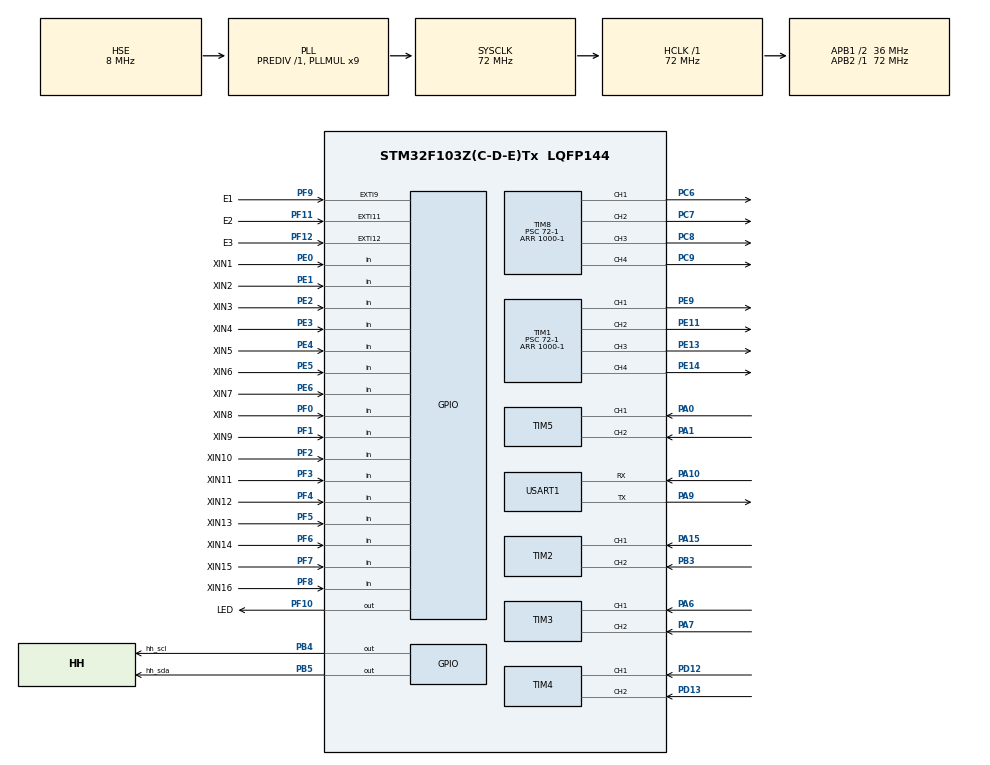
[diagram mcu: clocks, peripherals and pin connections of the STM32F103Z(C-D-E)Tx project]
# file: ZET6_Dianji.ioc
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Mcu.Family=STM32F1
Mcu.Name=STM32F103Z(C-D-E)Tx
Mcu.Package=LQFP144
NVIC.EXTI15_10_IRQn=true\:0\:0\:false\:false\:true\:true\:true\:true
NVIC.EXTI9_5_IRQn=true\:0\:0\:false\:false\:true\:true\:true\:true
NVIC.PriorityGroup=NVIC_PRIORITYGROUP_4
NVIC.TIM8_BRK_IRQn=true\:0\:0\:false\:false\:true\:true\:true\:true
NVIC.TIM8_CC_IRQn=true\:0\:0\:false\:false\:true\:true\:true\:true
NVIC.TIM8_TRG_COM_IRQn=true\:0\:0\:false\:false\:true\:true\:true\:true
NVIC.TIM8_UP_IRQn=true\:0\:0\:false\:false\:true\:true\:true\:true
OSC_IN.Mode=HSE-External-Oscillator
OSC_IN.Signal=RCC_OSC_IN
OSC_OUT.Mode=HSE-External-Oscillator
OSC_OUT.Signal=RCC_OSC_OUT
PA0-WKUP.Signal=S_TIM5_CH1
PA1.Signal=S_TIM5_CH2
PA10.Mode=Asynchronous
PA10.Signal=USART1_RX
PA13.Mode=Serial_Wire
PA13.Signal=SYS_JTMS-SWDIO
PA14.Mode=Serial_Wire
PA14.Signal=SYS_JTCK-SWCLK
PA15.Signal=S_TIM2_CH1_ETR
PA6.Signal=S_TIM3_CH1
PA7.Signal=S_TIM3_CH2
PA9.Mode=Asynchronous
PA9.Signal=USART1_TX
PB3.Signal=S_TIM2_CH2
PB4.GPIO_Label=hh_scl
PB4.GPIO_ModeDefaultOutputPP=GPIO_MODE_OUTPUT_OD
PB4.GPIO_PuPd=GPIO_PULLUP
PB4.GPIO_Speed=GPIO_SPEED_FREQ_HIGH
PB4.PinState=GPIO_PIN_SET
PB4.Signal=GPIO_Output
PB5.GPIO_Label=hh_sda
PB5.GPIO_ModeDefaultOutputPP=GPIO_MODE_OUTPUT_OD
PB5.GPIO_PuPd=GPIO_PULLUP
PB5.GPIO_Speed=GPIO_SPEED_FREQ_HIGH
PB5.PinState=GPIO_PIN_SET
PB5.Signal=GPIO_Output
PC6.Signal=S_TIM8_CH1
PC7.Signal=S_TIM8_CH2
PC8.Signal=S_TIM8_CH3
PC9.Signal=S_TIM8_CH4
PD12.Signal=S_TIM4_CH1
PD13.Signal=S_TIM4_CH2
PE0.GPIO_Label=XIN1
PE0.GPIO_PuPd=GPIO_PULLUP
PE0.Signal=GPIO_Input
PE1.GPIO_Label=XIN2
PE1.GPIO_PuPd=GPIO_PULLUP
PE1.Signal=GPIO_Input
PE11.Signal=S_TIM1_CH2
PE13.Signal=S_TIM1_CH3
PE14.Signal=S_TIM1_CH4
PE2.GPIO_Label=XIN3
PE2.GPIO_PuPd=GPIO_PULLUP
PE2.Signal=GPIO_Input
PE3.GPIO_Label=XIN4
PE3.GPIO_PuPd=GPIO_PULLUP
PE3.Signal=GPIO_Input
PE4.GPIO_Label=XIN5
PE4.GPIO_PuPd=GPIO_PULLUP
PE4.Signal=GPIO_Input
PE5.GPIO_Label=XIN6
PE5.GPIO_PuPd=GPIO_PULLUP
PE5.Signal=GPIO_Input
PE6.GPIO_Label=XIN7
PE6.GPIO_PuPd=GPIO_PULLUP
PE6.Signal=GPIO_Input
PE9.Signal=S_TIM1_CH1
PF0.GPIO_Label=XIN8
PF0.GPIO_PuPd=GPIO_PULLUP
PF0.Signal=GPIO_Input
PF1.GPIO_Label=XIN9
PF1.GPIO_PuPd=GPIO_PULLUP
PF1.Signal=GPIO_Input
PF10.GPIO_Label=LED
PF10.Signal=GPIO_Output
PF11.GPIO_Label=E2
PF11.GPIO_ModeDefaultEXTI=GPIO_MODE_IT_FALLING
PF11.GPIO_PuPd=GPIO_PULLUP
PF11.Signal=GPXTI11
PF12.GPIO_Label=E3
PF12.GPIO_ModeDefaultEXTI=GPIO_MODE_IT_FALLING
PF12.GPIO_PuPd=GPIO_PULLUP
PF12.Signal=GPXTI12
PF2.GPIO_Label=XIN10
PF2.GPIO_PuPd=GPIO_PULLUP
PF2.Signal=GPIO_Input
PF3.GPIO_Label=XIN11
PF3.GPIO_PuPd=GPIO_PULLUP
PF3.Signal=GPIO_Input
PF4.GPIO_Label=XIN12
PF4.GPIO_PuPd=GPIO_PULLUP
PF4.Signal=GPIO_Input
PF5.GPIO_Label=XIN13
PF5.GPIO_PuPd=GPIO_PULLUP
PF5.Signal=GPIO_Input
PF6.GPIO_Label=XIN14
PF6.GPIO_PuPd=GPIO_PULLUP
PF6.Signal=GPIO_Input
PF7.GPIO_Label=XIN15
PF7.GPIO_PuPd=GPIO_PULLUP
PF7.Signal=GPIO_Input
PF8.GPIO_Label=XIN16
PF8.GPIO_PuPd=GPIO_PULLUP
PF8.Signal=GPIO_Input
PF9.GPIO_Label=E1
PF9.GPIO_ModeDefaultEXTI=GPIO_MODE_IT_FALLING
PF9.GPIO_PuPd=GPIO_PULLUP
PF9.Signal=GPXTI9
ProjectManager.HeapSize=0x200
ProjectManager.StackSize=0x400
ProjectManager.TargetToolchain=MDK-ARM V5.32
RCC.AHBFreq_Value=72000000
RCC.APB1CLKDivider=RCC_HCLK_DIV2
RCC.APB1Freq_Value=36000000
RCC.APB1TimFreq_Value=72000000
RCC.APB2Freq_Value=72000000
RCC.APB2TimFreq_Value=72000000
RCC.HCLKFreq_Value=72000000
RCC.PLLMUL=RCC_PLL_MUL9
RCC.PLLSourceVirtual=RCC_PLLSOURCE_HSE
RCC.SYSCLKFreq_VALUE=72000000
RCC.SYSCLKSource=RCC_SYSCLKSOURCE_PLLCLK
RCC.USBFreq_Value=72000000
SH.S_TIM1_CH1.0=TIM1_CH1,PWM Generation1 CH1
SH.S_TIM1_CH2.0=TIM1_CH2,PWM Generation2 CH2
SH.S_TIM1_CH3.0=TIM1_CH3,PWM Generation3 CH3
SH.S_TIM1_CH4.0=TIM1_CH4,PWM Generation4 CH4
SH.S_TIM2_CH1_ETR.0=TIM2_CH1,Encoder_Interface
SH.S_TIM2_CH2.0=TIM2_CH2,Encoder_Interface
SH.S_TIM3_CH1.0=TIM3_CH1,Encoder_Interface
SH.S_TIM3_CH2.0=TIM3_CH2,Encoder_Interface
SH.S_TIM4_CH1.0=TIM4_CH1,Encoder_Interface
SH.S_TIM4_CH2.0=TIM4_CH2,Encoder_Interface
SH.S_TIM5_CH1.0=TIM5_CH1,Encoder_Interface
SH.S_TIM5_CH2.0=TIM5_CH2,Encoder_Interface
SH.S_TIM8_CH1.0=TIM8_CH1,PWM Generation1 CH1
SH.S_TIM8_CH2.0=TIM8_CH2,PWM Generation2 CH2
SH.S_TIM8_CH3.0=TIM8_CH3,PWM Generation3 CH3
SH.S_TIM8_CH4.0=TIM8_CH4,PWM Generation4 CH4
TIM1.AutoReloadPreload=TIM_AUTORELOAD_PRELOAD_ENABLE
TIM1.Channel-PWM\ Generation1\ CH1=TIM_CHANNEL_1
TIM1.Channel-PWM\ Generation2\ CH2=TIM_CHANNEL_2
TIM1.Channel-PWM\ Generation3\ CH3=TIM_CHANNEL_3
TIM1.Channel-PWM\ Generation4\ CH4=TIM_CHANNEL_4
TIM1.Period=1000-1
TIM1.Prescaler=72-1
TIM2.EncoderMode=TIM_ENCODERMODE_TI12
TIM3.EncoderMode=TIM_ENCODERMODE_TI12
TIM4.EncoderMode=TIM_ENCODERMODE_TI12
TIM5.EncoderMode=TIM_ENCODERMODE_TI12
TIM8.AutoReloadPreload=TIM_AUTORELOAD_PRELOAD_ENABLE
TIM8.Channel-PWM\ Generation1\ CH1=TIM_CHANNEL_1
TIM8.Channel-PWM\ Generation2\ CH2=TIM_CHANNEL_2
TIM8.Channel-PWM\ Generation3\ CH3=TIM_CHANNEL_3
TIM8.Channel-PWM\ Generation4\ CH4=TIM_CHANNEL_4
TIM8.Period=1000-1
TIM8.Prescaler=72-1
USART1.VirtualMode=VM_ASYNC
VP_TIM1_VS_ClockSourceINT.Mode=Internal
VP_TIM8_VS_ClockSourceINT.Mode=Internal
board=custom

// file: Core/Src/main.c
/* USER CODE BEGIN Header */
/**
  ******************************************************************************
  * @file           : main.c
  * @brief          : Main program body
  ******************************************************************************
  * @attention
  *
  * Copyright (c) 2024 STMicroelectronics.
  * All rights reserved.
  *
  * This software is licensed under terms that can be found in the LICENSE file
  * in the root directory of this software component.
  * If no LICENSE file comes with this software, it is provided AS-IS.
  *
  ******************************************************************************
  */
/* USER CODE END Header */
#include "main.h"
#include "tim.h"
#include "usart.h"
#include "gpio.h"

void SystemClock_Config(void);

int main(void)
{

  /* MCU Configuration--------------------------------------------------------*/

  /* Reset of all peripherals, Initializes the Flash interface and the Systick. */
  HAL_Init();

  /* Configure the system clock */
  SystemClock_Config();

  /* Initialize all configured peripherals */
  MX_GPIO_Init();
  MX_TIM1_Init();
  MX_TIM2_Init();
  MX_TIM3_Init();
  MX_TIM4_Init();
  MX_TIM5_Init();
  MX_TIM8_Init();
  MX_USART1_UART_Init();
  /* USER CODE BEGIN 2 */

	Scheduler_Init();
	//extern Motor_t right_motor;

  /* USER CODE END 2 */

  /* Infinite loop */
  while (1)
  {

    /* USER CODE BEGIN 3 */

		Scheduler_Run();
		//Set_PWM(250,150,150,150);

  }
  /* USER CODE END 3 */
}

void SystemClock_Config(void)
{
  RCC_OscInitTypeDef RCC_OscInitStruct = {0};
  RCC_ClkInitTypeDef RCC_ClkInitStruct = {0};

  /** Initializes the RCC Oscillators according to the specified parameters
  * in the RCC_OscInitTypeDef structure.
  */
  RCC_OscInitStruct.OscillatorType = RCC_OSCILLATORTYPE_HSE;
  RCC_OscInitStruct.HSEState = RCC_HSE_ON;
  RCC_OscInitStruct.HSEPredivValue = RCC_HSE_PREDIV_DIV1;
  RCC_OscInitStruct.HSIState = RCC_HSI_ON;
  RCC_OscInitStruct.PLL.PLLState = RCC_PLL_ON;
  RCC_OscInitStruct.PLL.PLLSource = RCC_PLLSOURCE_HSE;
  RCC_OscInitStruct.PLL.PLLMUL = RCC_PLL_MUL9;
  if (HAL_RCC_OscConfig(&RCC_OscInitStruct) != HAL_OK)
  {
    Error_Handler();
  }

  /** Initializes the CPU, AHB and APB buses clocks
  */
  RCC_ClkInitStruct.ClockType = RCC_CLOCKTYPE_HCLK|RCC_CLOCKTYPE_SYSCLK
                              |RCC_CLOCKTYPE_PCLK1|RCC_CLOCKTYPE_PCLK2;
  RCC_ClkInitStruct.SYSCLKSource = RCC_SYSCLKSOURCE_PLLCLK;
  RCC_ClkInitStruct.AHBCLKDivider = RCC_SYSCLK_DIV1;
  RCC_ClkInitStruct.APB1CLKDivider = RCC_HCLK_DIV2;
  RCC_ClkInitStruct.APB2CLKDivider = RCC_HCLK_DIV1;

  if (HAL_RCC_ClockConfig(&RCC_ClkInitStruct, FLASH_LATENCY_2) != HAL_OK)
  {
    Error_Handler();
  }
}

void Error_Handler(void)
{
  __disable_irq();
  while (1)
  {
  }
}
